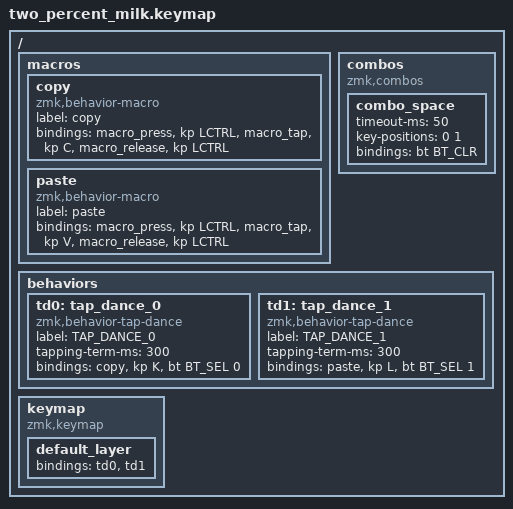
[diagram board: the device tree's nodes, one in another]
/*
 * Copyright (c) 2022 The ZMK Contributors
 *
 * SPDX-License-Identifier: MIT
 */

#include <behaviors.dtsi>
#include <dt-bindings/zmk/keys.h>
#include <dt-bindings/zmk/bt.h>

/ {
    macros {
        copy: copy {
            label = "copy";
            compatible = "zmk,behavior-macro";
            #binding-cells = <0>;
            bindings
                = <&macro_press &kp LCTRL>
                , <&macro_tap &kp C>
                , <&macro_release &kp LCTRL>
                ;
        };
    };
    macros {
        paste: paste {
            label = "paste";
            compatible = "zmk,behavior-macro";
            #binding-cells = <0>;
            bindings
                = <&macro_press &kp LCTRL>
                , <&macro_tap &kp V>
                , <&macro_release &kp LCTRL>
                ;
        };
    };
    combos {
        compatible = "zmk,combos";
        combo_space {
            timeout-ms = <50>;
            key-positions = <0 1>;
            bindings = <&bt BT_CLR>;
        };
    };
    behaviors {
        td0: tap_dance_0 {
            compatible = "zmk,behavior-tap-dance";
            label = "TAP_DANCE_0";
            #binding-cells = <0>;
            tapping-term-ms = <300>;
            bindings = <&copy>, <&kp K>, <&bt BT_SEL 0>;
        };
        td1: tap_dance_1 {
            compatible = "zmk,behavior-tap-dance";
            label = "TAP_DANCE_1";
            #binding-cells = <0>;
            tapping-term-ms = <300>;
            bindings = <&paste>, <&kp L>, <&bt BT_SEL 1>;
        };  
    };

    keymap {
        compatible = "zmk,keymap";

        default_layer {
            bindings = <
                &td0
                &td1
            >;
        };
    };
};
